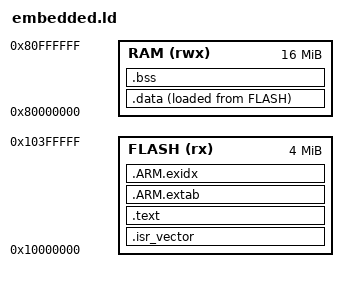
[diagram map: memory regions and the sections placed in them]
ENTRY(Reset_Handler)

/* QEMU surrogate map for Cortex-M33 (`mps2-an505`), used only by the
 * qemu-stm32h5 test target. The STM32H5 archive build does not link. */
MEMORY
{
  FLASH (rx)  : ORIGIN = 0x10000000, LENGTH = 4M
  RAM   (rwx) : ORIGIN = 0x80000000, LENGTH = 16M
}

_estack = ORIGIN(RAM) + LENGTH(RAM);

SECTIONS
{
  .isr_vector :
  {
    KEEP(*(.isr_vector))
  } > FLASH

  .text :
  {
    *(.text*)
    *(.rodata*)
    *(.init)
    *(.fini)
    *(.glue_7)
    *(.glue_7t)
    *(.eh_frame*)
  } > FLASH

  .ARM.extab :
  {
    *(.ARM.extab* .gnu.linkonce.armextab.*)
  } > FLASH

  .ARM.exidx :
  {
    __exidx_start = .;
    *(.ARM.exidx* .gnu.linkonce.armexidx.*)
    __exidx_end = .;
  } > FLASH

  .data :
  {
    _sdata = .;
    *(.data*)
    _edata = .;
  } > RAM AT > FLASH
  _sidata = LOADADDR(.data);

  .bss (NOLOAD) :
  {
    _sbss = .;
    *(.bss*)
    *(COMMON)
    _ebss = .;
  } > RAM

  . = ALIGN(8);
  end = .;
  _end = .;
}
